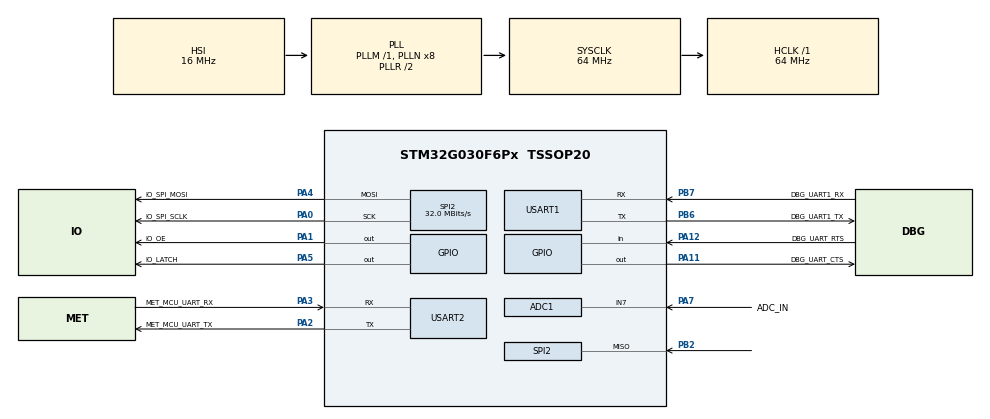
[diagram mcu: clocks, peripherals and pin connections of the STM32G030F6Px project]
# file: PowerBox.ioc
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ADC1.Channel-0\#ChannelRegularConversion=ADC_CHANNEL_7
ADC1.NbrOfConversionFlag=1
ADC1.Rank-0\#ChannelRegularConversion=1
ADC1.SamplingTime-0\#ChannelRegularConversion=ADC_SAMPLINGTIME_COMMON_1
ADC1.SelectedChannel=ADC_CHANNEL_7
ADC1.master=1
Mcu.Family=STM32G0
Mcu.Name=STM32G030F6Px
Mcu.Package=TSSOP20
NVIC.USART1_IRQn=true\:0\:0\:false\:false\:true\:true\:true\:true
NVIC.USART2_IRQn=true\:0\:0\:false\:false\:true\:true\:true\:true
PA0.GPIO_Label=IO_SPI_SCLK
PA0.Mode=Full_Duplex_Master
PA0.Signal=SPI2_SCK
PA1.GPIO_Label=IO_OE
PA1.Signal=GPIO_Output
PA11\ [PA9].GPIO_Label=DBG_UART_CTS
PA11\ [PA9].Signal=GPIO_Output
PA12\ [PA10].GPIO_Label=DBG_UART_RTS
PA12\ [PA10].Signal=GPIO_Input
PA13.Mode=Serial_Wire
PA13.Signal=SYS_SWDIO
PA14-BOOT0.Mode=Serial_Wire
PA14-BOOT0.Signal=SYS_SWCLK
PA14-BOOT0__PA15.StandardMode=true
PA2.GPIO_Label=MET_MCU_UART_TX
PA2.Mode=Asynchronous
PA2.Signal=USART2_TX
PA3.GPIO_Label=MET_MCU_UART_RX
PA3.Mode=Asynchronous
PA3.Signal=USART2_RX
PA4.GPIO_Label=IO_SPI_MOSI
PA4.Mode=Full_Duplex_Master
PA4.Signal=SPI2_MOSI
PA5.GPIO_Label=IO_LATCH
PA5.Signal=GPIO_Output
PA7.GPIO_Label=ADC_IN
PA7.Mode=IN7
PA7.Signal=ADC1_IN7
PB0__PB1__PB2__PA8.StandardMode=true
PB2.Mode=Full_Duplex_Master
PB2.Signal=SPI2_MISO
PB3__PB4__PB5__PB6.StandardMode=true
PB6.GPIO_Label=DBG_UART1_TX
PB6.Mode=Asynchronous
PB6.Signal=USART1_TX
PB7.GPIO_Label=DBG_UART1_RX
PB7.Mode=Asynchronous
PB7.Signal=USART1_RX
PB7__PB8.StandardMode=true
PC14-OSC32_IN\ (PC14)__PB9.StandardMode=true
ProjectManager.HeapSize=0x200
ProjectManager.StackSize=0x400
ProjectManager.TargetToolchain=EWARM V8.50
RCC.ADCFreq_Value=64000000
RCC.AHBFreq_Value=64000000
RCC.CortexFreq_Value=64000000
RCC.EXTERNAL_CLOCK_VALUE=12288000
RCC.HCLKFreq_Value=64000000
RCC.HSE_VALUE=8000000
RCC.HSI_VALUE=16000000
RCC.LSE_VALUE=32768
RCC.SYSCLKFreq_VALUE=64000000
RCC.SYSCLKSource=RCC_SYSCLKSOURCE_PLLCLK
RCC.VCOOutputFreq_Value=128000000
SPI2.CalculateBaudRate=32.0 MBits/s
SPI2.Direction=SPI_DIRECTION_2LINES
SPI2.Mode=SPI_MODE_MASTER
SPI2.VirtualType=VM_MASTER
USART1.VirtualMode-Asynchronous=VM_ASYNC
USART2.VirtualMode-Asynchronous=VM_ASYNC
board=custom

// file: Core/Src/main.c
/* USER CODE BEGIN Header */
/**
 ******************************************************************************
 * @file           : main.c
 * @brief          : Main program body
 ******************************************************************************
 * @attention
 *
 * Copyright (c) 2023 STMicroelectronics.
 * All rights reserved.
 *
 * This software is licensed under terms that can be found in the LICENSE file
 * in the root directory of this software component.
 * If no LICENSE file comes with this software, it is provided AS-IS.
 *
 ******************************************************************************
 */
/* USER CODE END Header */
#include "main.h"
#include "adc.h"
#include "spi.h"
#include "usart.h"
#include "gpio.h"

/* USER CODE BEGIN Includes */
#include <io_ext.h>
#include <app.main.h>
/* USER CODE END Includes */

void SystemClock_Config(void);

int main(void)
{

  /* MCU Configuration--------------------------------------------------------*/

  /* Reset of all peripherals, Initializes the Flash interface and the Systick. */
  HAL_Init();

  /* Configure the system clock */
  SystemClock_Config();

  /* Initialize all configured peripherals */
  MX_GPIO_Init();
  MX_ADC1_Init();
  MX_SPI2_Init();
  MX_USART1_UART_Init();
  MX_USART2_UART_Init();
  /* USER CODE BEGIN 2 */

  dbg_uart_init();

  ioext_init();

  app_main();
  /* USER CODE END 2 */

  /* Infinite loop */
  while (1)
  {

  }
}

void SystemClock_Config(void)
{
  RCC_OscInitTypeDef RCC_OscInitStruct = {0};
  RCC_ClkInitTypeDef RCC_ClkInitStruct = {0};

  /** Configure the main internal regulator output voltage
  */
  HAL_PWREx_ControlVoltageScaling(PWR_REGULATOR_VOLTAGE_SCALE1);

  /** Initializes the RCC Oscillators according to the specified parameters
  * in the RCC_OscInitTypeDef structure.
  */
  RCC_OscInitStruct.OscillatorType = RCC_OSCILLATORTYPE_HSI;
  RCC_OscInitStruct.HSIState = RCC_HSI_ON;
  RCC_OscInitStruct.HSIDiv = RCC_HSI_DIV1;
  RCC_OscInitStruct.HSICalibrationValue = RCC_HSICALIBRATION_DEFAULT;
  RCC_OscInitStruct.PLL.PLLState = RCC_PLL_ON;
  RCC_OscInitStruct.PLL.PLLSource = RCC_PLLSOURCE_HSI;
  RCC_OscInitStruct.PLL.PLLM = RCC_PLLM_DIV1;
  RCC_OscInitStruct.PLL.PLLN = 8;
  RCC_OscInitStruct.PLL.PLLP = RCC_PLLP_DIV2;
  RCC_OscInitStruct.PLL.PLLR = RCC_PLLR_DIV2;
  if (HAL_RCC_OscConfig(&RCC_OscInitStruct) != HAL_OK)
  {
    Error_Handler();
  }

  /** Initializes the CPU, AHB and APB buses clocks
  */
  RCC_ClkInitStruct.ClockType = RCC_CLOCKTYPE_HCLK|RCC_CLOCKTYPE_SYSCLK
                              |RCC_CLOCKTYPE_PCLK1;
  RCC_ClkInitStruct.SYSCLKSource = RCC_SYSCLKSOURCE_PLLCLK;
  RCC_ClkInitStruct.AHBCLKDivider = RCC_SYSCLK_DIV1;
  RCC_ClkInitStruct.APB1CLKDivider = RCC_HCLK_DIV1;

  if (HAL_RCC_ClockConfig(&RCC_ClkInitStruct, FLASH_LATENCY_2) != HAL_OK)
  {
    Error_Handler();
  }
}

void Error_Handler(void)
{
  __disable_irq();
  while (1)
  {
  }
}
